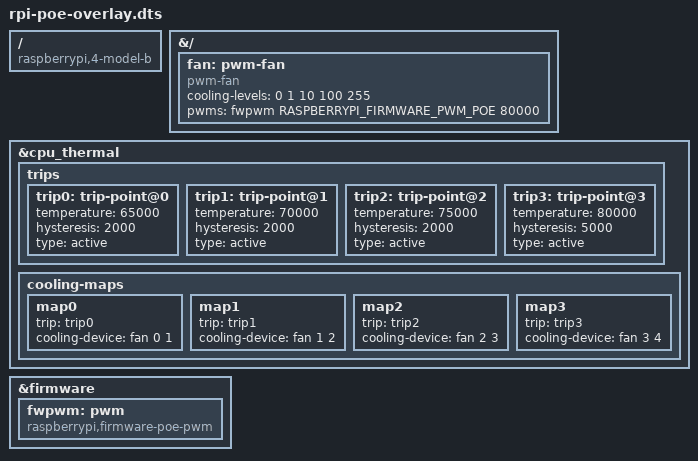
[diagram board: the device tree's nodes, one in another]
/dts-v1/;
/plugin/;

#include <dt-bindings/pwm/raspberrypi,firmware-poe-pwm.h>

/ {
  compatible = "raspberrypi,4-model-b", "brcm,bcm2711";
};

&{/} {
  fan: pwm-fan {
    compatible = "pwm-fan";
    cooling-levels = <0 1 10 100 255>;
    #cooling-cells = <2>;
    pwms = <&fwpwm RASPBERRYPI_FIRMWARE_PWM_POE 80000>;
  };
};

&cpu_thermal {
  trips {
    trip0: trip-point@0 {
      temperature = <65000>;
      hysteresis = <2000>;
      type = "active";
    };

    trip1: trip-point@1 {
      temperature = <70000>;
      hysteresis = <2000>;
      type = "active";
    };

    trip2: trip-point@2 {
      temperature = <75000>;
      hysteresis = <2000>;
      type = "active";
    };

    trip3: trip-point@3 {
      temperature = <80000>;
      hysteresis = <5000>;
      type = "active";
    };
  };

  cooling-maps {
    map0 {
      trip = <&trip0>;
      cooling-device = <&fan 0 1>;
    };

    map1 {
      trip = <&trip1>;
      cooling-device = <&fan 1 2>;
    };

    map2 {
      trip = <&trip2>;
      cooling-device = <&fan 2 3>;
    };

    map3 {
      trip = <&trip3>;
      cooling-device = <&fan 3 4>;
    };
  };
};

&firmware {
  fwpwm: pwm {
    compatible = "raspberrypi,firmware-poe-pwm";
    #pwm-cells = <2>;
  };
};
